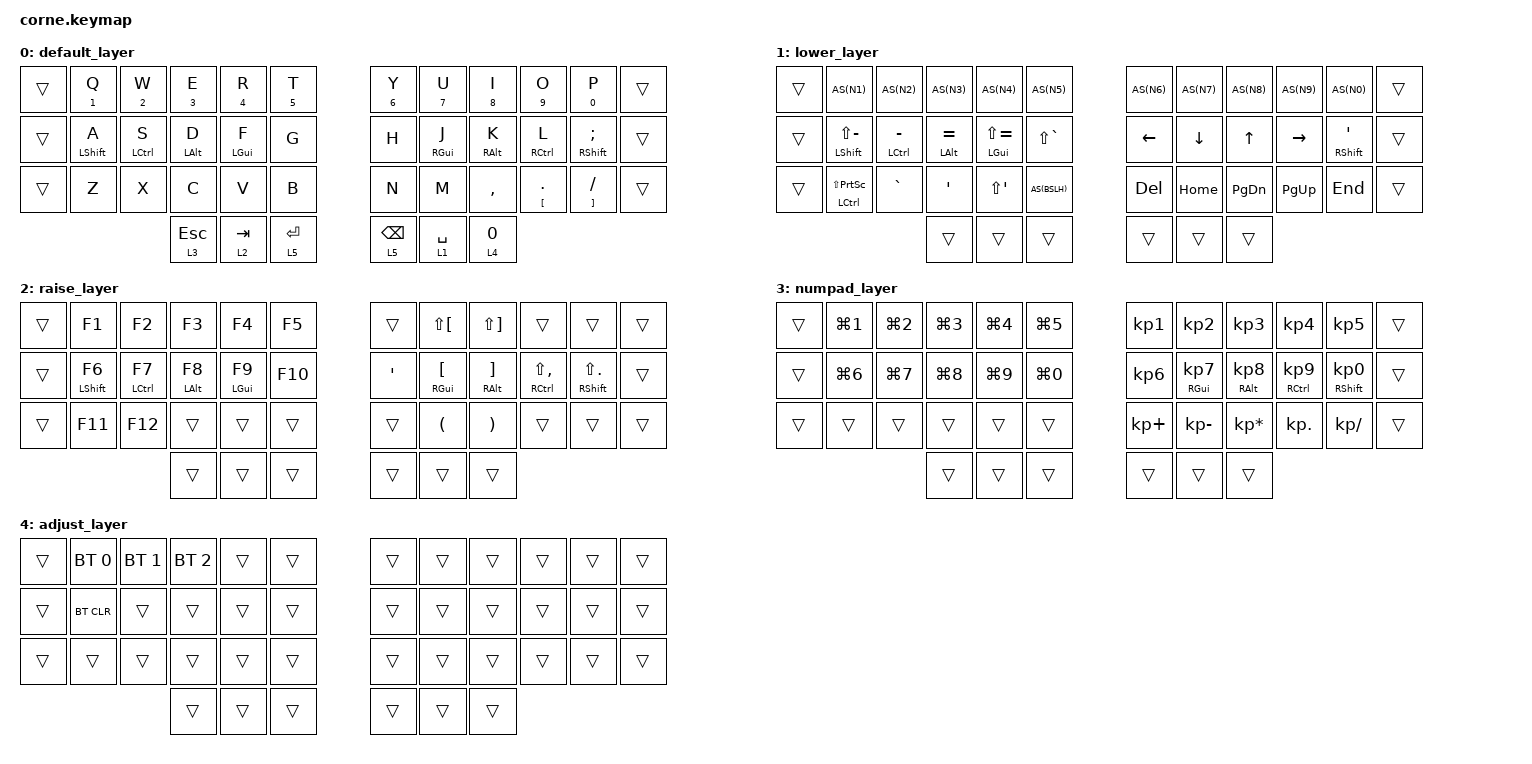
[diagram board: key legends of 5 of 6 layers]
#include <behaviors.dtsi>
#include <dt-bindings/zmk/keys.h>
#include <dt-bindings/zmk/bt.h>
#include <dt-bindings/zmk/mouse.h>

#define AS(k) &mt_ LS(k) k

/ {
    combos {
        compatible = "zmk,combos";
        combo_esc {
            timeout-ms = <20>;
            key-positions = <19 20>;
            bindings = <&kp ESC>;
        };
        combo_tilde_slash {
            timeout-ms = <20>;
            key-positions = <14 15>;
            bindings = <&tilde_slash>;
        };
        combo_vim_save {
            timeout-ms = <20>;
            key-positions = <31 32>;
            bindings = <&vim_save>;
        };
        combo_vim_quit {
            timeout-ms = <20>;
            key-positions = <30 31>;
            bindings = <&vim_quit>;
        };
        combo_scroll_lock {
            timeout-ms = <20>;
            key-positions = <15 16>;
            bindings = <&kp SLCK>;
        };
        combo_minus {
            timeout-ms = <20>;
            key-positions = <20 21>;
            bindings = <&kp MINUS>;
        };
        combo_email {
            timeout-ms = <20>;
            key-positions = <4 7>;
            bindings = <&email>;
        };
    };

    macros {
        tilde_slash: tilde_slash {
            compatible = "zmk,behavior-macro";
            #binding-cells = <0>;
            bindings = <&kp LS(GRAVE) &kp FSLH>;
        };
        vim_save: vim_save {
            compatible = "zmk,behavior-macro";
            #binding-cells = <0>;
            bindings = <&kp LS(SEMI) &kp W &kp RET>;
        };
        vim_quit: vim_quit {
            compatible = "zmk,behavior-macro";
            #binding-cells = <0>;
            bindings = <&kp LS(SEMI) &kp Q>;
        };
        email: email {
            compatible = "zmk,behavior-macro";
            #binding-cells = <0>;
            bindings = <&kp D &kp M &kp O &kp Z &kp Z &kp H &kp E &kp R &kp I &kp N &kp LS(N2) &kp G &kp M &kp A &kp I &kp L &kp DOT &kp C &kp O &kp M>;
        };
    };

    behaviors {
        // Customized mod_tap and layer_tap:
        // - mod_tap is 'tap preferred' as it's used on home-row
        // - layer_tap uses balanced flavor
        mt_: custom_mod_tap {
            compatible = "zmk,behavior-hold-tap";
            label = "MOD_TAP";
            #binding-cells = <2>;
            flavor = "tap-preferred";
            tapping-term-ms = <180>;
            quick-tap-ms = <180>;
            bindings = <&kp>, <&kp>;
        };
        lt_: custom_layer_tap {
            compatible = "zmk,behavior-hold-tap";
            label = "LAYER_TAP";
            #binding-cells = <2>;
            flavor = "balanced";
            tapping-term-ms = <180>;
            quick-tap-ms = <180>;
            bindings = <&mo>, <&kp>;
        };
        lt_cw: layer_tap_caps_word {
            compatible = "zmk,behavior-hold-tap";
            #binding-cells = <2>;
            tapping-term-ms = <180>;
            bindings = <&mo>, <&caps_word>;
        };
    };

// Layer 0
    keymap {
            compatible = "zmk,keymap";

            default_layer {
                    bindings = <
// ┌──────┬──────┬──────┬──────┬──────┬──────╥──────┬──────┬──────┬──────┬──────┬──────┐
// │      │  Q   │  W   │  E   │  R   │  T   ║  Y   │  U   │  I   │  O   │  P   │      │
// │      │ (1)  │ (2)  │ (3)  │ (4)  │ (5)  ║ (6)  │ (7)  │ (8)  │ (9)  │ (0)  │      │
// ├──────┼──────┼──────┼──────┼──────┼──────╫──────┼──────┼──────┼──────┼──────┼──────┤
// │      │  A   │  S   │  D   │  F   │  G   ║  H   │  J   │  K   │  L   │  ;   │      │
// │      │(SHFT)│(CTL) │(ALT) │(GUI) │      ║      │(GUI) │(ALT) │(CTL) │(SHFT)│      │
// ├──────┼──────┼──────┼──────┼──────┼──────╫──────┼──────┼──────┼──────┼──────┼──────┤
// │      │  Z   │  X   │  C   │  V   │  B   ║  N   │  M   │  ,   │  .   │  /   │      │
// │      │      │      │      │      │      ║      │      │      │ ([)  │ (L4) │      │
// └──────┴──────┴──────┴──────┴──────┴──────╨──────┴──────┴──────┴──────┴──────┴──────┘
//                      ┌──────┬──────┬──────╥──────┬──────┬──────┐
//                      │ ESC  │ TAB  │ RET  ║ BKSP │ SPC  │ CAPS │
//                      │ (L3) │ (L2) │ (L5) ║ (L5) │ (L1) │      │
//                      └──────┴──────┴──────╨──────┴──────┴──────┘
&trans   &mt_ N1 Q    &mt_ N2 W    &mt_ N3 E    &mt_ N4 R    &mt_ N5 T    &mt_ N6 Y    &mt_ N7 U    &mt_ N8 I    &mt_ N9 O    &mt_ N0 P    &trans
&trans   &mt_ LSHFT A &mt_ LCTRL S &mt_ LALT D  &mt_ LGUI F  &kp G        &kp H        &mt_ RGUI J  &mt_ RALT K  &mt_ RCTRL L &mt_ RSHFT SEMI &trans
&trans   &kp Z        &kp X        &kp C        &kp V        &kp B        &kp N        &kp M        &kp COMMA    &mt_ LBKT DOT &mt_ RBKT FSLH &trans
                                   &lt_ 3 ESC   &lt_ 2 TAB   &lt_ 5 RET   &lt_ 5 BKSP   &lt_ 1 SPC   &lt_ 4 0
                    >;
            };

// Layer 1
            lower_layer {
                    bindings = <
// ┌──────┬──────┬──────┬──────┬──────┬──────╥──────┬──────┬──────┬──────┬──────┬──────┐
// │      │  1!  │  2@  │  3#  │  4$  │  5%  ║  6^  │  7&  │  8*  │  9(  │  0)  │      │
// ├──────┼──────┼──────┼──────┼──────┼──────╫──────┼──────┼──────┼──────┼──────┼──────┤
// │      │  _   │  -   │  =   │  +   │  ~   ║  ←   │  ↓   │  ↑   │  →   │  '   │      │
// │      │(SHFT)│(CTL) │(ALT) │(GUI) │      ║      │      │      │      │(SHFT)│      │
// ├──────┼──────┼──────┼──────┼──────┼──────╫──────┼──────┼──────┼──────┼──────┼──────┤
// │      │sPRNT │  `   │  '   │  "   │  \|  ║ DEL  │ HOME │ PGDN │ PGUP │ END  │      │
// │      │(CTRL)│      │      │      │      ║      │      │      │      │      │      │
// └──────┴──────┴──────┴──────┴──────┴──────╨──────┴──────┴──────┴──────┴──────┴──────┘
//                      ┌──────┬──────┬──────╥──────┬──────┬──────┐
//                      │      │      │      ║      │      │      │
//                      └──────┴──────┴──────╨──────┴──────┴──────┘
&trans   AS(N1)               AS(N2)           AS(N3)            AS(N4)              AS(N5)        AS(N6)       AS(N7)           AS(N8)       AS(N9)     AS(N0)          &trans
&trans   &mt_ LSHFT LS(MINUS) &mt_ LCTRL MINUS &mt_ LALT EQUAL   &mt_ LGUI LS(EQUAL) &kp LS(GRAVE) &kp LEFT     &kp DOWN         &kp UP       &kp RIGHT  &mt_ RSHFT SQT &trans
&trans   &mt_ LCTRL LS(PSCRN)        &kp GRAVE        &kp SQT           &kp LS(SQT)         AS(BSLH)      &kp DEL      &kp HOME         &kp PG_DN    &kp PG_UP  &kp END         &trans
                                               &trans            &trans              &trans        &trans       &trans           &trans
                    >;
            };

// Layer 2
            raise_layer {
                    bindings = <
// ┌──────┬──────┬──────┬──────┬──────┬──────╥──────┬──────┬──────┬──────┬──────┬──────┐
// │      │  F1  │  F2  │  F3  │  F4  │  F5  ║      │  {   │  }   │      │      │      │
// ├──────┼──────┼──────┼──────┼──────┼──────╫──────┼──────┼──────┼──────┼──────┼──────┤
// │      │  F6  │  F7  │  F8  │  F9  │  F10 ║  '"  │  [   │  ]   │  <   │  >   │      │
// │      │(SHFT)│(CTL) │(ALT) │(GUI) │      ║      │(GUI) │(ALT) │(CTL) │(SHFT)│      │
// ├──────┼──────┼──────┼──────┼──────┼──────╫──────┼──────┼──────┼──────┼──────┼──────┤
// │      │  F11 │  F12 │      │      │      ║      │  (   │  )   │      │      │      │
// └──────┴──────┴──────┴──────┴──────┴──────╨──────┴──────┴──────┴──────┴──────┴──────┘
//                      ┌──────┬──────┬──────╥──────┬──────┬──────┐
//                      │      │      │      ║      │      │      │
//                      └──────┴──────┴──────╨──────┴──────┴──────┘
&trans   &kp F1        &kp F2        &kp F3       &kp F4       &kp F5       &trans       &kp LS(LBKT)   &kp LS(RBKT)   &trans               &trans             &trans
&trans   &mt_ LSHFT F6 &mt_ LCTRL F7 &mt_ LALT F8 &mt_ LGUI F9 &kp F10      &kp SQT      &mt_ RGUI LBKT &mt_ RALT RBKT &mt_ RCTRL LS(COMMA) &mt_ RSHFT LS(DOT) &trans
&trans   &kp F11       &kp F12       &trans       &trans       &trans       &trans       &kp LPAR       &kp RPAR       &trans               &trans             &trans
                                     &trans       &trans       &trans       &trans       &trans         &trans
                    >;
            };

// Layer 3
            numpad_layer {
                    bindings = <
// ┌──────┬──────┬──────┬──────┬──────┬──────╥──────┬──────┬──────┬──────┬──────┬──────┐
// │      │ ⌘1   │ ⌘2   │ ⌘3   │ ⌘4   │ ⌘5   ║  1   │  2   │  3   │  4   │  5   │      │
// ├──────┼──────┼──────┼──────┼──────┼──────╫──────┼──────┼──────┼──────┼──────┼──────┤
// │      │ ⌘6   │ ⌘7   │ ⌘8   │ ⌘9   │ ⌘0   ║  6   │  7   │  8   │  9   │  0   │      │
// │      │      │      │      │      │      ║      │(GUI) │(ALT) │(CTL) │(SHFT)│      │
// ├──────┼──────┼──────┼──────┼──────┼──────╫──────┼──────┼──────┼──────┼──────┼──────┤
// │      │      │      │      │      │      ║  +   │  -   │  *   │  .   │  /   │      │
// └──────┴──────┴──────┴──────┴──────┴──────╨──────┴──────┴──────┴──────┴──────┴──────┘
//                      ┌──────┬──────┬──────╥──────┬──────┬──────┐
//                      │      │      │      ║      │      │      │
//                      └──────┴──────┴──────╨──────┴──────┴──────┘
&trans &kp LG(N1) &kp LG(N2) &kp LG(N3) &kp LG(N4) &kp LG(N5)   &kp KP_N1    &kp KP_N2          &kp KP_N3          &kp KP_N4           &kp KP_N5           &trans
&trans &kp LG(N6) &kp LG(N7) &kp LG(N8) &kp LG(N9) &kp LG(N0)   &kp KP_N6    &mt_ RGUI KP_N7    &mt_ RALT KP_N8    &mt_ RCTRL KP_N9    &mt_ RSHFT KP_N0    &trans
&trans &trans     &trans     &trans     &trans     &trans       &kp KP_PLUS  &kp KP_MINUS       &kp KP_MULTIPLY    &kp KP_DOT          &kp KP_DIVIDE       &trans
                             &trans     &trans     &trans       &trans       &trans             &trans
                    >;
            };

// Layer 4
            adjust_layer {
                    bindings = <
// ┌──────┬──────┬──────┬──────┬──────┬──────╥──────┬──────┬──────┬──────┬──────┬──────┐
// │      │ BT 0 │ BT 1 │ BT 2 │      │      ║      │      │      │      │      │      │
// ├──────┼──────┼──────┼──────┼──────┼──────╫──────┼──────┼──────┼──────┼──────┼──────┤
// │      │BTCLR │      │      │      │      ║      │      │      │      │      │      │
// ├──────┼──────┼──────┼──────┼──────┼──────╫──────┼──────┼──────┼──────┼──────┼──────┤
// │      │      │      │      │      │      ║      │      │      │      │      │      │
// └──────┴──────┴──────┴──────┴──────┴──────╨──────┴──────┴──────┴──────┴──────┴──────┘
//                      ┌──────┬──────┬──────╥──────┬──────┬──────┐
//                      │      │      │      ║      │      │      │
//                      └──────┴──────┴──────╨──────┴──────┴──────┘
&trans &bt BT_SEL 0 &bt BT_SEL 1 &bt BT_SEL 2 &trans &trans &trans &trans &trans &trans &trans &trans
&trans &bt BT_CLR &trans &trans &trans &trans &trans &trans &trans &trans &trans &trans
&trans &trans &trans &trans &trans &trans &trans &trans &trans &trans &trans &trans
&trans &trans &trans &trans &trans &trans
                    >;
            };

// Layer 5
            mouse_layer {
                    bindings = <
// ┌──────┬──────┬──────┬──────┬──────┬──────╥──────┬──────┬──────┬──────┬──────┬──────┐
// │      │      │      │      │      │ SCL↑ ║ ↖    │      │      │ ↗    │      │      │
// ├──────┼──────┼──────┼──────┼──────┼──────╫──────┼──────┼──────┼──────┼──────┼──────┤
// │      │      │ RCLK │ MCLK │ LCLK │ SCL↓ ║ ←    │ ↓    │ ↑    │ →    │      │      │
// ├──────┼──────┼──────┼──────┼──────┼──────╫──────┼──────┼──────┼──────┼──────┼──────┤
// │      │      │      │      │      │      ║ ↙    │      │      │ ↘    │      │      │
// └──────┴──────┴──────┴──────┴──────┴──────╨──────┴──────┴──────┴──────┴──────┴──────┘
//                      ┌──────┬──────┬──────╥──────┬──────┬──────┐
//                      │      │      │ (L5) ║ (L5) │      │      │
//                      └──────┴──────┴──────╨──────┴──────┴──────┘
&trans &trans    &trans    &trans    &trans    &msc SCRL_UP   &mmv (MOVE_LEFT|MOVE_UP)   &trans &trans &mmv (MOVE_RIGHT|MOVE_UP) &trans &trans
&trans &trans    &mkp RCLK &mkp MCLK &mkp LCLK &msc SCRL_DOWN &mmv MOVE_LEFT             &mmv MOVE_DOWN &mmv MOVE_UP &mmv MOVE_RIGHT &trans &trans
&trans &trans    &trans    &trans    &trans    &trans         &mmv (MOVE_LEFT|MOVE_DOWN)  &trans &trans &mmv (MOVE_RIGHT|MOVE_DOWN) &trans &trans
&trans &trans &trans &trans &trans &trans
                    >;
            };
        };
};
